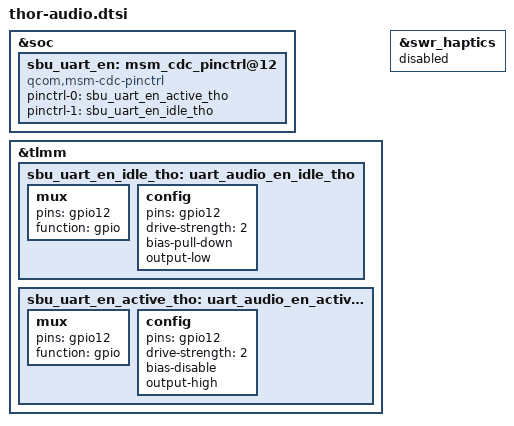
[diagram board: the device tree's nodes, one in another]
#include "xiaomi-sm8450-common.dtsi"

&soc {
    sbu_uart_en: msm_cdc_pinctrl@12 {
        compatible = "qcom,msm-cdc-pinctrl";
        pinctrl-names = "aud_active", "aud_sleep";
        pinctrl-0 = <&sbu_uart_en_active_tho>;
        pinctrl-1 = <&sbu_uart_en_idle_tho>;
        #gpio-cells = <0>;
    };
};

&tlmm {
	sbu_uart_en_idle_tho: uart_audio_en_idle_tho {
		mux {
			pins = "gpio12";
			function = "gpio";
		};
		config {
			pins = "gpio12";
			drive-strength = <2>;
			bias-pull-down;
			output-low;
		};
	};

	sbu_uart_en_active_tho: uart_audio_en_active_tho {
		mux {
			pins = "gpio12";
			function = "gpio";
		};
		config {
			pins = "gpio12";
			drive-strength = <2>;
			bias-disable;
			output-high;
		};
	};
};

&swr_haptics {
	status = "disabled";
};
